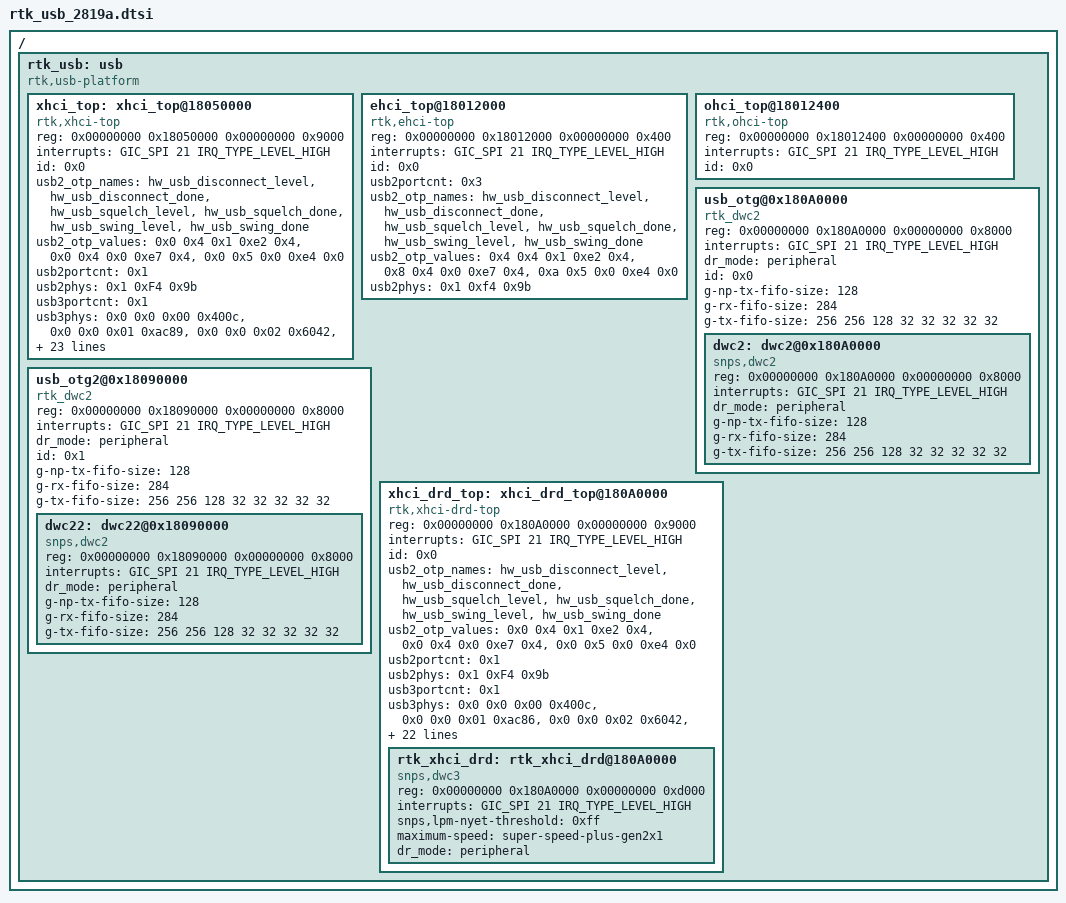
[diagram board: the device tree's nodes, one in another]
/*
 * RTK TV usb host driver device tree in the 64 bits version;
 * including the base address, parameters of phy etc.
 *
 */

/ {
	#address-cells = <1>;
	#size-cells = <1>;
	rtk_usb: usb {
		compatible = "rtk,usb-platform";
		#address-cells = <2>;
		#size-cells = <2>;
	       ranges;

		xhci_top: xhci_top@18050000 {
			compatible = "rtk,xhci-top";
			reg = <0x00000000 0x18050000 0x00000000 0x9000>;
			interrupts = <GIC_SPI 21 IRQ_TYPE_LEVEL_HIGH>;
			id = <0x0>;
			usb2_otp_names = "hw_usb_disconnect_level", "hw_usb_disconnect_done",
			                             "hw_usb_squelch_level", "hw_usb_squelch_done",
			                             "hw_usb_swing_level", "hw_usb_swing_done";
			                             
			usb2_otp_values = <0x0 0x4 0x1 0xe2 0x4>,/* otp_offset/bitsnum/page/reg/bits_offset */
							<0x0 0x4 0x0 0xe7 0x4>,
							<0x0 0x5 0x0 0xe4 0x0>;
							
			usb2portcnt = <0x1>;
			usb2phys = <0x1 0xF4 0x9b>;
				    
		usb3portcnt = <0x1>;		    
		usb3phys =  <0x0 0x0 0x00 0x400c>,
				    <0x0 0x0 0x01 0xac89>,
				    <0x0 0x0 0x02 0x6042>,
				    <0x0 0x0 0x03 0x2771>,
				    <0x0 0x0 0x04 0x72f5>,
				    <0x0 0x0 0x05 0x2ad3>,
				    <0x0 0x0 0x06 0x0017>,
				    <0x0 0x0 0x07 0x2e00>,
				    <0x0 0x0 0x08 0x3591>,
				    <0x0 0x0 0x0A 0x9610>,
				    <0x0 0x0 0x0B 0x990d>,
				    <0x0 0x0 0x0C 0xf008>, 
				    <0x0 0x0 0x0D 0xef26>,
				    <0x0 0x0 0x0E 0x1010>,
				    <0x0 0x0 0x0F 0x8f50>,
				    <0x0 0x0 0x10 0x000c>,
				    <0x0 0x0 0x11 0x4c10>,
				    <0x0 0x0 0x12 0x0000>,
				    <0x0 0x0 0x13 0x0c81>,
				    <0x0 0x0 0x14 0xde01>,
				    <0x0 0x0 0x15 0x0000>,
				    <0x0 0x0 0x16 0x0000>,
				    <0x0 0x0 0x17 0x0000>,
				    <0x0 0x0 0x18 0x0000>,
				    <0x0 0x0 0x19 0x6000>,
				    <0x0 0x0 0x1A 0x0085>,
				    <0x0 0x0 0x1B 0x2014>,
				    <0x0 0x0 0x1C 0xc900>,
				    <0x0 0x0 0x1D 0xa03f>,
				    <0x0 0x0 0x1E 0xc2e0>, 
				    <0x0 0x0 0x1F 0x7e00>,
				    <0x0 0x1 0x00 0x7025>,
				    <0x0 0x1 0x01 0xf543>, 
				    <0x0 0x1 0x02 0x0003>,
				    <0x0 0x1 0x03 0x0b62>,
				    <0x0 0x1 0x04 0x4770>,
				    <0x0 0x1 0x05 0x10ec>, 
				    <0x0 0x1 0x06 0x840a>,
				    <0x0 0x1 0x07 0x01d6>,
				    <0x0 0x1 0x08 0xf802>,
				    <0x0 0x1 0x09 0xff00>, 
				    <0x0 0x1 0x0A 0x3071>,
				    <0x0 0x1 0x0B 0x8028>,
				    <0x0 0x1 0x0C 0xffff>, 
				    <0x0 0x1 0x0D 0xffff>,
				    <0x0 0x1 0x0E 0x0000>,
				    <0x0 0x1 0x0F 0x8600>;
                        disable_parkmode = "true";
		};

		ehci_top@18012000 {
			compatible = "rtk,ehci-top";
			reg = <0x00000000 0x18012000 0x00000000 0x400>;
            interrupts = <GIC_SPI 21 IRQ_TYPE_LEVEL_HIGH>;
            id = <0x0>;
            usb2portcnt = <0x3>;
            usb2_otp_names = "hw_usb_disconnect_level", "hw_usb_disconnect_done",
			                             "hw_usb_squelch_level", "hw_usb_squelch_done",
			                             "hw_usb_swing_level", "hw_usb_swing_done";
			                             
			usb2_otp_values = <0x4 0x4 0x1 0xe2 0x4>,/* otp_offset/bitsnum/page/reg/bits_offset */
							<0x8 0x4 0x0 0xe7 0x4>,
							<0xa 0x5 0x0 0xe4 0x0>;
			usb2phys = <0x1  0xf4  0x9b>;
		};

		ohci_top@18012400 {
			compatible = "rtk,ohci-top";
			reg = <0x00000000 0x18012400 0x00000000 0x400>;
			interrupts = <GIC_SPI 21 IRQ_TYPE_LEVEL_HIGH>;
			id = <0x0>;
		};	

		usb_otg@0x180A0000 {
			compatible = "rtk_dwc2";
			reg = <0x00000000 0x180A0000 0x00000000 0x8000>;
			interrupts = <GIC_SPI 21 IRQ_TYPE_LEVEL_HIGH>;
			dr_mode ="peripheral";
			id = <0x0>;
			g-np-tx-fifo-size = <128>;
			g-rx-fifo-size = <284>;
			g-tx-fifo-size = <256 256 128 32 32 32 32 32>;			
			/**for dwc2 otg**/
			#address-cells = <2>;
			#size-cells = <2>;
			ranges;
			dwc2: dwc2@0x180A0000 {
				compatible = "snps,dwc2";
				reg = <0x00000000 0x180A0000 0x00000000 0x8000>;
				interrupts = <GIC_SPI 21 IRQ_TYPE_LEVEL_HIGH>;
				dr_mode ="peripheral";
				g-np-tx-fifo-size = <128>;
				g-rx-fifo-size = <284>;
				g-tx-fifo-size = <256 256 128 32 32 32 32 32>;
			};
		};

		usb_otg2@0x18090000 {
			compatible = "rtk_dwc2";
			reg = <0x00000000 0x18090000 0x00000000 0x8000>;
			interrupts = <GIC_SPI 21 IRQ_TYPE_LEVEL_HIGH>;
			dr_mode ="peripheral";
			id = <0x1>;
			g-np-tx-fifo-size = <128>;
			g-rx-fifo-size = <284>;
			g-tx-fifo-size = <256 256 128 32 32 32 32 32>;			
			/**for dwc2 otg**/
			#address-cells = <2>;
			#size-cells = <2>;
			ranges;
			dwc22: dwc22@0x18090000 {
				compatible = "snps,dwc2";
				reg = <0x00000000 0x18090000 0x00000000 0x8000>;
				interrupts = <GIC_SPI 21 IRQ_TYPE_LEVEL_HIGH>;
				dr_mode ="peripheral";
				g-np-tx-fifo-size = <128>;
				g-rx-fifo-size = <284>;
				g-tx-fifo-size = <256 256 128 32 32 32 32 32>;
			};
		};

		xhci_drd_top: xhci_drd_top@180A0000 {
			compatible = "rtk,xhci-drd-top";
			reg = <0x00000000 0x180A0000 0x00000000 0x9000>;
			interrupts = <GIC_SPI 21 IRQ_TYPE_LEVEL_HIGH>;
			id = <0x0>;
			usb2_otp_names = "hw_usb_disconnect_level", "hw_usb_disconnect_done",
			                             "hw_usb_squelch_level", "hw_usb_squelch_done",
			                             "hw_usb_swing_level", "hw_usb_swing_done";
			                             
			usb2_otp_values = <0x0 0x4 0x1 0xe2 0x4>,/* otp_offset/bitsnum/page/reg/bits_offset */
							<0x0 0x4 0x0 0xe7 0x4>,
							<0x0 0x5 0x0 0xe4 0x0>;

			usb2portcnt = <0x1>;
			usb2phys = <0x1 0xF4 0x9b>;
			usb3portcnt = <0x1>;
			usb3phys =  <0x0 0x0 0x00 0x400c>,
				    <0x0 0x0 0x01 0xac86>,
				    <0x0 0x0 0x02 0x6042>,
				    <0x0 0x0 0x03 0x2771>,
				    <0x0 0x0 0x04 0x72f5>,
				    <0x0 0x0 0x05 0x2ad3>,
				    <0x0 0x0 0x06 0x0006>,
				    <0x0 0x0 0x07 0x2e00>,
				    <0x0 0x0 0x08 0x3591>,
				    <0x0 0x0 0x0A 0xa608>,
				    <0x0 0x0 0x0B 0xb905>,
				    <0x0 0x0 0x0C 0xc008>, 
				    <0x0 0x0 0x0D 0xef1a>,
				    <0x0 0x0 0x0E 0x1010>,
				    <0x0 0x0 0x0F 0x8d50>,
				    <0x0 0x0 0x10 0x000c>,
				    <0x0 0x0 0x11 0x4c10>,
				    <0x0 0x0 0x12 0x0000>,
				    <0x0 0x0 0x13 0x0c81>,
				    <0x0 0x0 0x14 0xde01>,
				    <0x0 0x0 0x15 0x0000>,
				    <0x0 0x0 0x16 0x0000>,
				    <0x0 0x0 0x17 0x0000>,
				    <0x0 0x0 0x18 0x0000>,
				    <0x0 0x0 0x19 0x6000>,
				    <0x0 0x0 0x1A 0x0085>,
				    <0x0 0x0 0x1B 0x2014>,
				    <0x0 0x0 0x1C 0xc900>,
				    <0x0 0x0 0x1D 0xa03f>,
				    <0x0 0x0 0x1E 0xc2e0>, 
				    <0x0 0x0 0x1F 0x7e00>,
				    <0x0 0x1 0x00 0x7057>,
				    <0x0 0x1 0x01 0xf545>, 
				    <0x0 0x1 0x02 0x0013>,
				    <0x0 0x1 0x03 0xab66>,
				    <0x0 0x1 0x04 0x4770>,
				    <0x0 0x1 0x05 0x126c>, 
				    <0x0 0x1 0x06 0x840a>,
				    <0x0 0x1 0x07 0x01d6>,
				    <0x0 0x1 0x08 0xf802>,
				    <0x0 0x1 0x09 0xff00>, 
				    <0x0 0x1 0x0A 0x3050>,
				    <0x0 0x1 0x0B 0x8028>,
				    <0x0 0x1 0x0C 0xffff>, 
				    <0x0 0x1 0x0D 0xffff>,
				    <0x0 0x1 0x0E 0x0000>,
				    <0x0 0x1 0x0F 0x8600>;
				    
			/**for xhci drd**/
			#address-cells = <2>;
			#size-cells = <2>;
			ranges;
			/********
			*  the dwc3 driver's offset is 0xc100, we have to use (0x180D0000 - 0x4000)
			*********/
			rtk_xhci_drd: rtk_xhci_drd@180A0000 {
				compatible = "snps,dwc3";
				reg = <0x00000000 0x180A0000 0x00000000 0xd000>;
				interrupts = <GIC_SPI 21 IRQ_TYPE_LEVEL_HIGH>;
				snps,lpm-nyet-threshold = <0xff>;
				maximum-speed = "super-speed-plus-gen2x1";
				dr_mode = "peripheral";
			};
		};

		
	};

  };
